AUTOSAR XML (schema 4-2-2)
package /EB/SoftwareComponents
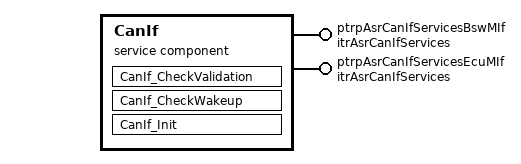
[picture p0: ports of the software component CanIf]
  service sw component type CanIf: category=ASR_Interfaces
    provide port ptrpAsrCanIfServicesBswMIf: provided-interface=itrAsrCanIfServices
    provide port ptrpAsrCanIfServicesEcuMIf: provided-interface=itrAsrCanIfServices
    behavior CanIf_IB: handle-termination-and-restart=NO-SUPPORT
      runnable CanIf_CheckValidation
      runnable CanIf_CheckWakeup
      runnable CanIf_Init
package /EB/TriggerInterfaces
  trigger interface itrAsrCanIfServices
    4 x trigger, all with trigger-period={cse-code=1000, cse-code-factor=0}:
      CanIf_CheckValidation
      CanIf_CheckWakeup
      CanIf_Init
      CanIf_SetControllerMode
